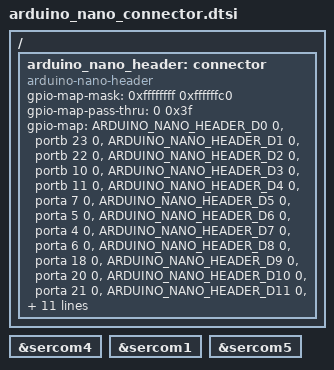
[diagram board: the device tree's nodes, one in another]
/*
 * Copyright (c) 2022 Joylab AG
 * SPDX-License-Identifier: Apache-2.0
 */

#include <zephyr/dt-bindings/gpio/arduino-nano-header.h>

/ {
	arduino_nano_header: connector {
		compatible = "arduino-nano-header";
		#gpio-cells = <2>;
		gpio-map-mask = <0xffffffff 0xffffffc0>;
		gpio-map-pass-thru = <0 0x3f>;
		gpio-map = <ARDUINO_NANO_HEADER_D0 0 &portb 23 0>,  /* D0 / UART-RX */
			   <ARDUINO_NANO_HEADER_D1 0 &portb 22 0>,  /* D1 / UART-TX */
			   <ARDUINO_NANO_HEADER_D2 0 &portb 10 0>,  /* D2 */
			   <ARDUINO_NANO_HEADER_D3 0 &portb 11 0>,  /* D3 */
			   <ARDUINO_NANO_HEADER_D4 0 &porta 7 0>,   /* D4 */
			   <ARDUINO_NANO_HEADER_D5 0 &porta 5 0>,   /* D5 */
			   <ARDUINO_NANO_HEADER_D6 0 &porta 4 0>,   /* D6 */
			   <ARDUINO_NANO_HEADER_D7 0 &porta 6 0>,   /* D7 */
			   <ARDUINO_NANO_HEADER_D8 0 &porta 18 0>,  /* D8 */
			   <ARDUINO_NANO_HEADER_D9 0 &porta 20 0>,  /* D9 */
			   <ARDUINO_NANO_HEADER_D10 0 &porta 21 0>, /* D10 */
			   <ARDUINO_NANO_HEADER_D11 0 &porta 16 0>, /* D11 / SPI-MOSI */
			   <ARDUINO_NANO_HEADER_D12 0 &porta 19 0>, /* D12 / SPI-MISO */
			   <ARDUINO_NANO_HEADER_D13 0 &porta 17 0>, /* D13 / SPI-SCK */
			   <ARDUINO_NANO_HEADER_D14 0 &porta 2 0>,  /* D14 / A0 */
			   <ARDUINO_NANO_HEADER_D15 0 &portb 2 0>,  /* D15 / A1 */
			   <ARDUINO_NANO_HEADER_D16 0 &porta 11 0>, /* D16 / A2 */
			   <ARDUINO_NANO_HEADER_D17 0 &porta 10 0>, /* D17 / A3 */
			   <ARDUINO_NANO_HEADER_D18 0 &portb 8 0>,  /* D18 / A4 / I2C-SDA */
			   <ARDUINO_NANO_HEADER_D19 0 &portb 9 0>,  /* D19 / A5 / I2C-SCL */
			   <ARDUINO_NANO_HEADER_D20 0 &porta 9 0>,  /* D20 / A6 */
			   <ARDUINO_NANO_HEADER_D21 0 &portb 3 0>;  /* D21 / A7 */
	};
};

arduino_nano_i2c: &sercom4 {};

arduino_nano_spi: &sercom1 {};

arduino_nano_serial: &sercom5 {};
